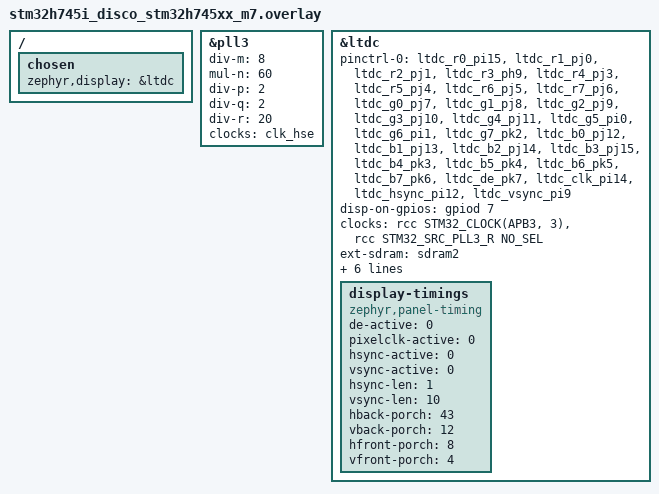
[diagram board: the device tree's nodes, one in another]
#include <zephyr/dt-bindings/display/panel.h>

/ {
	chosen {
		zephyr,display = &ltdc;
	};
};

/* PLL3R outputs ~9.375 MHz for the LTDC pixel clock */
&pll3 {
	div-m = <8>;
	mul-n = <60>;
	div-p = <2>;
	div-q = <2>;
	div-r = <20>;
	clocks = <&clk_hse>;
	status = "okay";
};

&ltdc {
	status = "okay";

	pinctrl-0 = <
		&ltdc_r0_pi15 &ltdc_r1_pj0 &ltdc_r2_pj1 &ltdc_r3_ph9
		&ltdc_r4_pj3 &ltdc_r5_pj4 &ltdc_r6_pj5 &ltdc_r7_pj6
		&ltdc_g0_pj7 &ltdc_g1_pj8 &ltdc_g2_pj9 &ltdc_g3_pj10
		&ltdc_g4_pj11 &ltdc_g5_pi0 &ltdc_g6_pi1 &ltdc_g7_pk2
		&ltdc_b0_pj12 &ltdc_b1_pj13 &ltdc_b2_pj14 &ltdc_b3_pj15
		&ltdc_b4_pk3 &ltdc_b5_pk4 &ltdc_b6_pk5 &ltdc_b7_pk6
		&ltdc_de_pk7 &ltdc_clk_pi14 &ltdc_hsync_pi12 &ltdc_vsync_pi9
	>;

	pinctrl-names = "default";

	disp-on-gpios = <&gpiod 7 GPIO_ACTIVE_HIGH>;

	clocks = <&rcc STM32_CLOCK(APB3, 3)>,
		 <&rcc STM32_SRC_PLL3_R NO_SEL>;

	ext-sdram = <&sdram2>;

	width = <480>;
	height = <272>;

	pixel-format = <PANEL_PIXEL_FORMAT_RGB_888>;

	display-timings {
		compatible = "zephyr,panel-timing";

		de-active = <0>;
		pixelclk-active = <0>;
		hsync-active = <0>;
		vsync-active = <0>;

		hsync-len = <1>;
		vsync-len = <10>;

		hback-porch = <43>;
		vback-porch = <12>;

		hfront-porch = <8>;
		vfront-porch = <4>;
	};

	def-back-color-red = <0>;
	def-back-color-green = <0>;
	def-back-color-blue = <0>;
};
